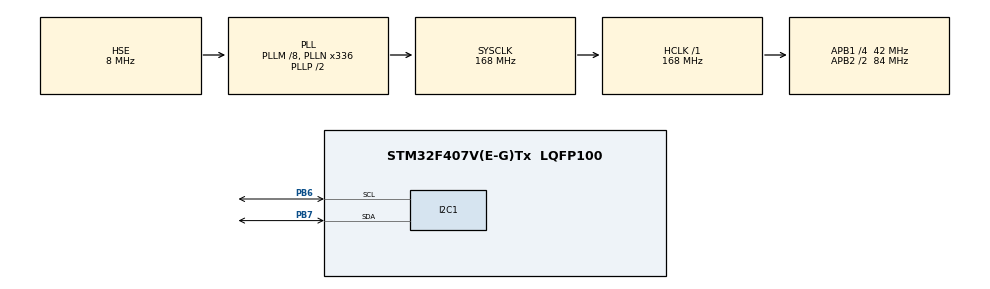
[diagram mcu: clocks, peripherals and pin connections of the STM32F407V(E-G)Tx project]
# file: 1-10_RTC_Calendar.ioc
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Mcu.Family=STM32F4
Mcu.Name=STM32F407V(E-G)Tx
Mcu.Package=LQFP100
NVIC.PriorityGroup=NVIC_PRIORITYGROUP_4
PA13.Mode=Serial_Wire
PA13.Signal=SYS_JTMS-SWDIO
PA14.Mode=Serial_Wire
PA14.Signal=SYS_JTCK-SWCLK
PB6.Mode=I2C
PB6.Signal=I2C1_SCL
PB7.Mode=I2C
PB7.Signal=I2C1_SDA
PC14-OSC32_IN.Mode=LSE-External-Oscillator
PC14-OSC32_IN.Signal=RCC_OSC32_IN
PC15-OSC32_OUT.Mode=LSE-External-Oscillator
PC15-OSC32_OUT.Signal=RCC_OSC32_OUT
PH0-OSC_IN.Mode=HSE-External-Oscillator
PH0-OSC_IN.Signal=RCC_OSC_IN
PH1-OSC_OUT.Mode=HSE-External-Oscillator
PH1-OSC_OUT.Signal=RCC_OSC_OUT
ProjectManager.HeapSize=0x200
ProjectManager.StackSize=0x400
ProjectManager.TargetToolchain=STM32CubeIDE
RCC.48MHZClocksFreq_Value=84000000
RCC.AHBFreq_Value=168000000
RCC.APB1CLKDivider=RCC_HCLK_DIV4
RCC.APB1Freq_Value=42000000
RCC.APB1TimFreq_Value=84000000
RCC.APB2CLKDivider=RCC_HCLK_DIV2
RCC.APB2Freq_Value=84000000
RCC.APB2TimFreq_Value=168000000
RCC.CortexFreq_Value=168000000
RCC.HCLKFreq_Value=168000000
RCC.HSE_VALUE=8000000
RCC.HSI_VALUE=16000000
RCC.PLLM=8
RCC.PLLN=336
RCC.PLLSourceVirtual=RCC_PLLSOURCE_HSE
RCC.RCC_RTC_Clock_Source=RCC_RTCCLKSOURCE_LSE
RCC.RCC_RTC_Clock_SourceVirtual=RCC_RTCCLKSOURCE_LSE
RCC.SYSCLKFreq_VALUE=168000000
RCC.SYSCLKSource=RCC_SYSCLKSOURCE_PLLCLK
RCC.VCOOutputFreq_Value=336000000
VP_RTC_VS_RTC_Activate.Mode=RTC_Enabled
VP_RTC_VS_RTC_Calendar.Mode=RTC_Calendar
board=custom

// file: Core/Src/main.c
/* USER CODE BEGIN Header */
/**
  ******************************************************************************
  * @file           : main.c
  * @brief          : Main program body
  ******************************************************************************
  * @attention
  *
  * Copyright (c) 2025 STMicroelectronics.
  * All rights reserved.
  *
  * This software is licensed under terms that can be found in the LICENSE file
  * in the root directory of this software component.
  * If no LICENSE file comes with this software, it is provided AS-IS.
  *
  ******************************************************************************
  */
/* USER CODE END Header */
#include "main.h"
#include "i2c.h"
#include "gpio.h"

/* USER CODE BEGIN Includes */
#include "..\..\User\rtc\rtc.h"
#include "..\..\User\OLED\oled.h"
/* USER CODE END Includes */

void SystemClock_Config(void);

int main(void)
{

  /* MCU Configuration--------------------------------------------------------*/

  /* Reset of all peripherals, Initializes the Flash interface and the Systick. */
  HAL_Init();

  /* USER CODE BEGIN Init */
  OLED_Init();
  /* USER CODE END Init */

  /* Configure the system clock */
  SystemClock_Config();

  /* Initialize all configured peripherals */
  MX_GPIO_Init();
  MX_I2C1_Init();
  /* USER CODE BEGIN 2 */

  OLED_Init();

  /* USER CODE END 2 */

  /* Infinite loop */
  /* USER CODE BEGIN WHILE */
  while (1)
  {
		if(USART1_RX_STA&0xC000){ //如果标志位是0xC000表示收到数据串完成，可以处理。
		   if((USART1_RX_STA&0x3FFF)==0){ //单独的回车键再显示一次欢迎词
			   RTC_Get();//读出当前RTC日期与时间，放入全局变量
			   printf(" 洋桃IoT开发板RTC实时时钟测试   \r\n");
			   printf(" 实时时间：%04d-%02d-%02d  %02d:%02d:%02d  \r\n",
					   ryear, rmon, rday, rhour, rmin, rsec);//显示日期时间
			   printf(" 单按回车键更新时间，输入字母C初始化时钟 \r\n");
			   printf(" 请输入设置时间，格式20170806120000，按回车键确定！ \r\n");
		   }else if((USART1_RX_STA&0x3FFF)==1){  //判断数据是不是1个
			   if(USART1_RX_BUF[0]=='c' ||  USART1_RX_BUF[0]=='C'){
				   MX_RTC_Init(); //键盘输入c或C，初始化时钟（调用HAL库自带的初始化函数）
				   printf("初始化成功！       \r\n");//显示初始化成功
			   }else{
				   printf("指令错误！           \r\n"); //显示指令错误！
			   }
		   }else if((USART1_RX_STA&0x3FFF)==14){ //判断数据是不是14个
			   //将超级终端发过来的数据换算并写入RTC
			   ryear = (USART1_RX_BUF[0]-0x30)*1000 + (USART1_RX_BUF[1]-0x30)*100 +
					   (USART1_RX_BUF[2]-0x30)*10 + (USART1_RX_BUF[3]-0x30);//减0x30得到十进制0~9的数据
			   rmon =  (USART1_RX_BUF[4]-0x30)*10 + (USART1_RX_BUF[5]-0x30);
			   rday =  (USART1_RX_BUF[6]-0x30)*10 + (USART1_RX_BUF[7]-0x30);
			   rhour = (USART1_RX_BUF[8]-0x30)*10 + (USART1_RX_BUF[9]-0x30);
			   rmin =  (USART1_RX_BUF[10]-0x30)*10 + (USART1_RX_BUF[11]-0x30);
			   rsec =  (USART1_RX_BUF[12]-0x30)*10 + (USART1_RX_BUF[13]-0x30);
			   if (RTC_Set(ryear,rmon,rday,rhour,rmin,rsec) != HAL_OK)//将数据写入RTC程序
			   {
				   printf("写入时间失败！        \r\n"); //显示写入失败
			   }else printf("写入成功！       \r\n");//显示写入成功
		   }else{ //如果以上都不是，即是错误的指令。
			   printf("指令错误！          \r\n");  //如果不是以上正确的操作，显示指令错误！
		   }
		   USART1_RX_STA=0; //将串口数据标志位清0
		}
    /* USER CODE END WHILE */
  }
}

void SystemClock_Config(void)
{
  RCC_OscInitTypeDef RCC_OscInitStruct = {0};
  RCC_ClkInitTypeDef RCC_ClkInitStruct = {0};

  /** Configure the main internal regulator output voltage
  */
  __HAL_RCC_PWR_CLK_ENABLE();
  __HAL_PWR_VOLTAGESCALING_CONFIG(PWR_REGULATOR_VOLTAGE_SCALE1);

  /** Initializes the RCC Oscillators according to the specified parameters
  * in the RCC_OscInitTypeDef structure.
  */
  RCC_OscInitStruct.OscillatorType = RCC_OSCILLATORTYPE_HSE|RCC_OSCILLATORTYPE_LSE;
  RCC_OscInitStruct.HSEState = RCC_HSE_ON;
  RCC_OscInitStruct.LSEState = RCC_LSE_ON;
  RCC_OscInitStruct.PLL.PLLState = RCC_PLL_ON;
  RCC_OscInitStruct.PLL.PLLSource = RCC_PLLSOURCE_HSE;
  RCC_OscInitStruct.PLL.PLLM = 8;
  RCC_OscInitStruct.PLL.PLLN = 336;
  RCC_OscInitStruct.PLL.PLLP = RCC_PLLP_DIV2;
  RCC_OscInitStruct.PLL.PLLQ = 4;
  if (HAL_RCC_OscConfig(&RCC_OscInitStruct) != HAL_OK)
  {
    Error_Handler();
  }

  /** Initializes the CPU, AHB and APB buses clocks
  */
  RCC_ClkInitStruct.ClockType = RCC_CLOCKTYPE_HCLK|RCC_CLOCKTYPE_SYSCLK
                              |RCC_CLOCKTYPE_PCLK1|RCC_CLOCKTYPE_PCLK2;
  RCC_ClkInitStruct.SYSCLKSource = RCC_SYSCLKSOURCE_PLLCLK;
  RCC_ClkInitStruct.AHBCLKDivider = RCC_SYSCLK_DIV1;
  RCC_ClkInitStruct.APB1CLKDivider = RCC_HCLK_DIV4;
  RCC_ClkInitStruct.APB2CLKDivider = RCC_HCLK_DIV2;

  if (HAL_RCC_ClockConfig(&RCC_ClkInitStruct, FLASH_LATENCY_5) != HAL_OK)
  {
    Error_Handler();
  }
}

void Error_Handler(void)
{
  __disable_irq();
  while (1)
  {
  }
}
